AUTOSAR XML (schema 3.1.2)
package /Components/SWC_AdvPrevKnkT
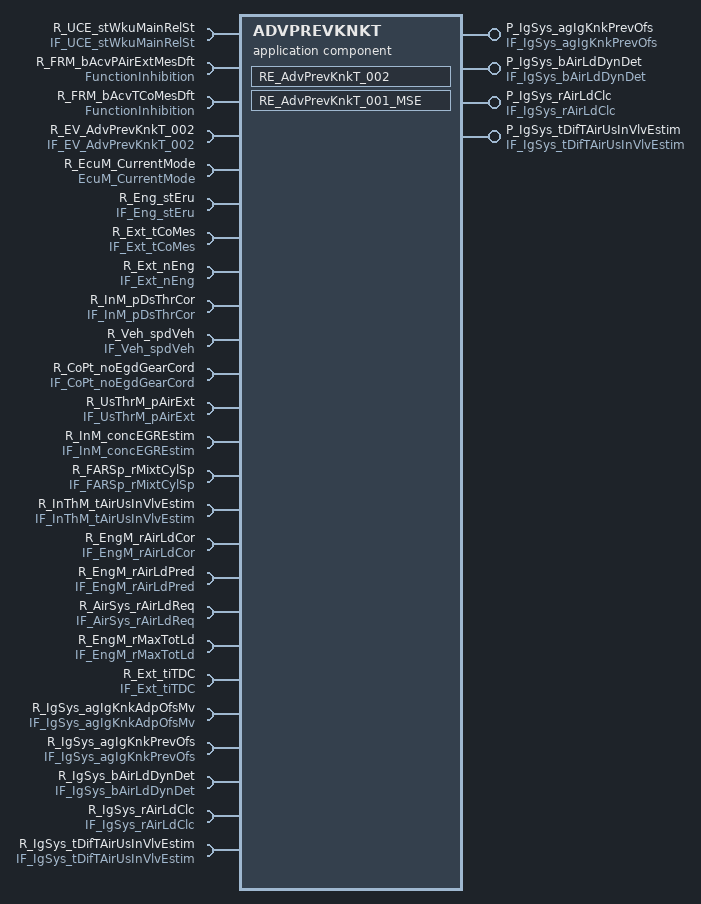
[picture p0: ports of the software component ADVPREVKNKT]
  application software component type ADVPREVKNKT  # AdvPrevKnkT
    require port R_UCE_stWkuMainRelSt: required-interface=IF_UCE_stWkuMainRelSt
    require port R_FRM_bAcvPAirExtMesDft: required-interface=FunctionInhibition
    require port R_FRM_bAcvTCoMesDft: required-interface=FunctionInhibition
    4 x provide port:
      P_IgSys_agIgKnkPrevOfs: unqueued-sender-com-spec{data-element=IgSys_agIgKnkPrevOfs, can-invalidate=false, init-value=ConstantValue}, provided-interface=IF_IgSys_agIgKnkPrevOfs
      P_IgSys_bAirLdDynDet: unqueued-sender-com-spec{data-element=IgSys_bAirLdDynDet, can-invalidate=false, init-value=ConstantValue1}, provided-interface=IF_IgSys_bAirLdDynDet
      P_IgSys_rAirLdClc: unqueued-sender-com-spec{data-element=IgSys_rAirLdClc, can-invalidate=false, init-value=ConstantValue3}, provided-interface=IF_IgSys_rAirLdClc
      P_IgSys_tDifTAirUsInVlvEstim: unqueued-sender-com-spec{data-element=IgSys_tDifTAirUsInVlvEstim, can-invalidate=false, init-value=SInt16InitValue}, provided-interface=IF_IgSys_tDifTAirUsInVlvEstim
    22 x require port:
      R_EV_AdvPrevKnkT_002: unqueued-receiver-com-spec{data-element=EV_AdvPrevKnkT_002, init-value=UInt8InitValue, resync-time=0}, required-interface=IF_EV_AdvPrevKnkT_002
      R_EcuM_CurrentMode: required-interface=EcuM_CurrentMode
      R_Eng_stEru: unqueued-receiver-com-spec{data-element=Eng_stEru, init-value=ConstantValue5, resync-time=0}, required-interface=IF_Eng_stEru
      R_Ext_tCoMes: unqueued-receiver-com-spec{data-element=Ext_tCoMes, init-value=ConstantValue7, resync-time=0}, required-interface=IF_Ext_tCoMes
      R_Ext_nEng: unqueued-receiver-com-spec{data-element=Ext_nEng, init-value=ConstantValue9, resync-time=0}, required-interface=IF_Ext_nEng
      R_InM_pDsThrCor: unqueued-receiver-com-spec{data-element=InM_pDsThrCor, init-value=ConstantValue11, resync-time=0}, required-interface=IF_InM_pDsThrCor
      R_Veh_spdVeh: unqueued-receiver-com-spec{data-element=Veh_spdVeh, init-value=ConstantValue13, resync-time=0}, required-interface=IF_Veh_spdVeh
      R_CoPt_noEgdGearCord: unqueued-receiver-com-spec{data-element=CoPt_noEgdGearCord, init-value=ConstantValue15, resync-time=0}, required-interface=IF_CoPt_noEgdGearCord
      R_UsThrM_pAirExt: unqueued-receiver-com-spec{data-element=UsThrM_pAirExt, init-value=ConstantValue17, resync-time=0}, required-interface=IF_UsThrM_pAirExt
      R_InM_concEGREstim: unqueued-receiver-com-spec{data-element=InM_concEGREstim, init-value=UInt16InitValue, resync-time=0}, required-interface=IF_InM_concEGREstim
      R_FARSp_rMixtCylSp: unqueued-receiver-com-spec{data-element=FARSp_rMixtCylSp, init-value=ConstantValue19, resync-time=0}, required-interface=IF_FARSp_rMixtCylSp
      R_InThM_tAirUsInVlvEstim: unqueued-receiver-com-spec{data-element=InThM_tAirUsInVlvEstim, init-value=ConstantValue21, resync-time=0}, required-interface=IF_InThM_tAirUsInVlvEstim
      R_EngM_rAirLdCor: unqueued-receiver-com-spec{data-element=EngM_rAirLdCor, init-value=ConstantValue23, resync-time=0}, required-interface=IF_EngM_rAirLdCor
      R_EngM_rAirLdPred: unqueued-receiver-com-spec{data-element=EngM_rAirLdPred, init-value=UInt16InitValue25, resync-time=0}, required-interface=IF_EngM_rAirLdPred
      R_AirSys_rAirLdReq: unqueued-receiver-com-spec{data-element=AirSys_rAirLdReq, init-value=UInt16InitValue27, resync-time=0}, required-interface=IF_AirSys_rAirLdReq
      R_EngM_rMaxTotLd: unqueued-receiver-com-spec{data-element=EngM_rMaxTotLd, init-value=UInt16InitValue29, resync-time=0}, required-interface=IF_EngM_rMaxTotLd
      R_Ext_tiTDC: unqueued-receiver-com-spec{data-element=Ext_tiTDC, init-value=ConstantValue31, resync-time=0}, required-interface=IF_Ext_tiTDC
      R_IgSys_agIgKnkAdpOfsMv: unqueued-receiver-com-spec{data-element=IgSys_agIgKnkAdpOfsMv, init-value=ConstantValue33, resync-time=0}, required-interface=IF_IgSys_agIgKnkAdpOfsMv
      R_IgSys_agIgKnkPrevOfs: unqueued-receiver-com-spec{data-element=IgSys_agIgKnkPrevOfs, init-value=ConstantValue, resync-time=0}, required-interface=IF_IgSys_agIgKnkPrevOfs
      R_IgSys_bAirLdDynDet: unqueued-receiver-com-spec{data-element=IgSys_bAirLdDynDet, init-value=ConstantValue35, resync-time=0}, required-interface=IF_IgSys_bAirLdDynDet
      R_IgSys_rAirLdClc: unqueued-receiver-com-spec{data-element=IgSys_rAirLdClc, init-value=ConstantValue37, resync-time=0}, required-interface=IF_IgSys_rAirLdClc
      R_IgSys_tDifTAirUsInVlvEstim: unqueued-receiver-com-spec{data-element=IgSys_tDifTAirUsInVlvEstim, init-value=SInt16InitValue, resync-time=0}, required-interface=IF_IgSys_tDifTAirUsInVlvEstim
  23 x constant specification:
    ConstantValue
      value:
        integer literal ConstantValue: type=DT_IgSys_agIgKnkPrevOfs, value=96
    ConstantValue1
      value:
        boolean literal ConstantValue1: type=DT_IgSys_bAirLdDynDet, value=false
    ConstantValue11
      value:
        integer literal ConstantValue11: type=DT_InM_pDsThrCor, value=0
    ConstantValue13
      value:
        integer literal ConstantValue13: type=DT_Veh_spdVeh, value=0
    ConstantValue15
      value:
        integer literal ConstantValue15: type=DT_CoPt_noEgdGearCord, value=0
    ConstantValue17
      value:
        integer literal ConstantValue17: type=DT_UsThrM_pAirExt, value=0
    ConstantValue19
      value:
        integer literal ConstantValue19: type=DT_FARSp_rMixtCylSp, value=4096
    ConstantValue21
      value:
        integer literal ConstantValue21: type=DT_InThM_tAirUsInVlvEstim, value=0
    ConstantValue23
      value:
        integer literal ConstantValue23: type=DT_EngM_rAirLdCor, value=0
    ConstantValue3
      value:
        integer literal ConstantValue3: type=DT_IgSys_rAirLdClc, value=0
    ConstantValue31
      value:
        integer literal ConstantValue31: type=DT_Ext_tiTDC, value=100
    ConstantValue33
      value:
        integer literal ConstantValue33: type=DT_IgSys_agIgKnkAdpOfsMv, value=96
    ConstantValue35
      value:
        boolean literal ConstantValue35: type=DT_IgSys_bAirLdDynDet, value=false
    ConstantValue37
      value:
        integer literal ConstantValue37: type=DT_IgSys_rAirLdClc, value=0
    ConstantValue5
      value:
        integer literal ConstantValue5: type=DT_Eng_stEru, value=1
    ConstantValue7
      value:
        integer literal ConstantValue7: type=DT_Ext_tCoMes, value=20
    ConstantValue9
      value:
        integer literal ConstantValue9: type=DT_Ext_nEng, value=0
    SInt16InitValue
      value:
        integer literal SInt16InitValue: type=DT_IgSys_tDifTAirUsInVlvEstim, value=-32768
    UInt16InitValue
      value:
        integer literal UInt16InitValue: type=DT_InM_concEGREstim, value=0
    UInt16InitValue25
      value:
        integer literal UInt16InitValue25: type=DT_EngM_rAirLdPred, value=0
    UInt16InitValue27
      value:
        integer literal UInt16InitValue27: type=DT_AirSys_rAirLdReq, value=0
    UInt16InitValue29
      value:
        integer literal UInt16InitValue29: type=DT_EngM_rMaxTotLd, value=0
    UInt8InitValue
      value:
        integer literal UInt8InitValue: type=DT_EV_AdvPrevKnkT_002, value=0
  internal behavior IB_AdvPrevKnkT: component=ADVPREVKNKT
    mode switch event EV_AdvPrevKnkT_001_MSE: start-on-event=RE_AdvPrevKnkT_001_MSE, activation=ENTRY, mode=R_EcuM_CurrentMode.currentMode.RUN
    data received event EV_AdvPrevKnkT_002: mode-dependency=dependent-on-mode=[R_UCE_stWkuMainRelSt.RCD_stWkuMainRelSt.PreMainWakeUp, R_UCE_stWkuMainRelSt.RCD_stWkuMainRelSt.PostMainWakeUp, R_UCE_stWkuMainRelSt.RCD_stWkuMainRelSt.Invalid], start-on-event=RE_AdvPrevKnkT_002, data=R_EV_AdvPrevKnkT_002.EV_AdvPrevKnkT_002
    runnable RE_AdvPrevKnkT_002
      21 x data receive point:
        DRP_R_IgSys_rAirLdClc_IgSys_rAirLdClc: data-element=R_IgSys_rAirLdClc.IgSys_rAirLdClc
        dr_FARSp_rMixtCylSp: data-element=R_FARSp_rMixtCylSp.FARSp_rMixtCylSp
        dr_AirSys_rAirLdReq: data-element=R_AirSys_rAirLdReq.AirSys_rAirLdReq
        dr_Veh_spdVeh: data-element=R_Veh_spdVeh.Veh_spdVeh
        dr_InM_pDsThrCor: data-element=R_InM_pDsThrCor.InM_pDsThrCor
        dr_CoPt_noEgdGearCord: data-element=R_CoPt_noEgdGearCord.CoPt_noEgdGearCord
        dr_InThM_tAirUsInVlvEstim: data-element=R_InThM_tAirUsInVlvEstim.InThM_tAirUsInVlvEstim
        dr_EV_AdvPrevKnkT_002: data-element=R_EV_AdvPrevKnkT_002.EV_AdvPrevKnkT_002
        dr_EngM_rAirLdCor: data-element=R_EngM_rAirLdCor.EngM_rAirLdCor
        dr_EngM_rMaxTotLd: data-element=R_EngM_rMaxTotLd.EngM_rMaxTotLd
        dr_Ext_tCoMes: data-element=R_Ext_tCoMes.Ext_tCoMes
        dr_IgSys_agIgKnkPrevOfs: data-element=R_IgSys_agIgKnkPrevOfs.IgSys_agIgKnkPrevOfs
        dr_UsThrM_pAirExt: data-element=R_UsThrM_pAirExt.UsThrM_pAirExt
        dr_Ext_tiTDC: data-element=R_Ext_tiTDC.Ext_tiTDC
        dr_EngM_rAirLdPred: data-element=R_EngM_rAirLdPred.EngM_rAirLdPred
        dr_IgSys_agIgKnkAdpOfsMv: data-element=R_IgSys_agIgKnkAdpOfsMv.IgSys_agIgKnkAdpOfsMv
        dr_InM_concEGREstim: data-element=R_InM_concEGREstim.InM_concEGREstim
        dr_IgSys_tDifTAirUsInVlvEstim: data-element=R_IgSys_tDifTAirUsInVlvEstim.IgSys_tDifTAirUsInVlvEstim
        dr_Eng_stEru: data-element=R_Eng_stEru.Eng_stEru
        DRP_R_IgSys_bAirLdDynDet_IgSys_bAirLdDynDet: data-element=R_IgSys_bAirLdDynDet.IgSys_bAirLdDynDet
        dr_Ext_nEng: data-element=R_Ext_nEng.Ext_nEng
      data send point ds_IgSys_bAirLdDynDet: data-element=P_IgSys_bAirLdDynDet.IgSys_bAirLdDynDet
      data send point ds_IgSys_rAirLdClc: data-element=P_IgSys_rAirLdClc.IgSys_rAirLdClc
      data send point ds_IgSys_tDifTAirUsInVlvEstim: data-element=P_IgSys_tDifTAirUsInVlvEstim.IgSys_tDifTAirUsInVlvEstim
      sync call ssp_FRM_bAcvTCoMesDft: operation=R_FRM_bAcvTCoMesDft.GetFunctionPermission
      sync call ssp_FRM_bAcvPAirExtMesDft: operation=R_FRM_bAcvPAirExtMesDft.GetFunctionPermission
    runnable RE_AdvPrevKnkT_001_MSE
      4 x data send point:
        ds_IgSys_agIgKnkPrevOfs: data-element=P_IgSys_agIgKnkPrevOfs.IgSys_agIgKnkPrevOfs
        ds_IgSys_rAirLdClc: data-element=P_IgSys_rAirLdClc.IgSys_rAirLdClc
        ds_IgSys_bAirLdDynDet: data-element=P_IgSys_bAirLdDynDet.IgSys_bAirLdDynDet
        ds_IgSys_tDifTAirUsInVlvEstim: data-element=P_IgSys_tDifTAirUsInVlvEstim.IgSys_tDifTAirUsInVlvEstim
  swc implementation Imp_AdvPrevKnkT: code-generator=Real-Time Workshop Embedded Coder 5.5 (R2010a) 25-Jan-2010, programming-language=C, behavior=IB_AdvPrevKnkT
    code-descriptors:
      code CodeDescriptor: type=SRC
        9 x xfile:
          AdvPrevKnkT_MemMap_h: url=AdvPrevKnkT_MemMap.h
          AdvPrevKnkT_import_h: url=AdvPrevKnkT_import.h
          AdvPrevKnkT_private_h: url=AdvPrevKnkT_private.h
          AdvPrevKnkT_Def_c: url=AdvPrevKnkT_Def.c
          AdvPrevKnkT_types_h: url=AdvPrevKnkT_types.h
          AdvPrevKnkT_Version_c: url=AdvPrevKnkT_Version.c
          AdvPrevKnkT_Version_h: url=AdvPrevKnkT_Version.h
          AdvPrevKnkT_c: url=AdvPrevKnkT.c
          AdvPrevKnkT_h: url=AdvPrevKnkT.h
